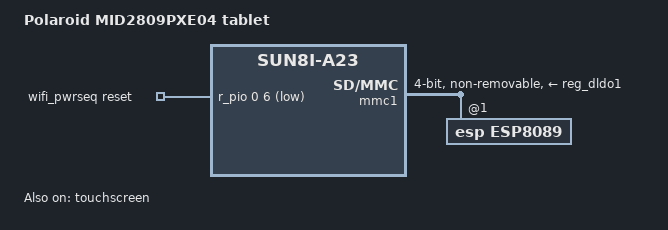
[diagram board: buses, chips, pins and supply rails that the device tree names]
/dts-v1/;
#include "sun8i-a23.dtsi"
#include "sun8i-reference-design-tablet.dtsi"
/ {
	model = "Polaroid MID2809PXE04 tablet";
	compatible = "polaroid,mid2809pxe04", "allwinner,sun8i-a23";
	aliases {
		ethernet0 = &esp8089;
	};
	wifi_pwrseq: wifi_pwrseq {
		compatible = "mmc-pwrseq-simple";
		reset-gpios = <&r_pio 0 6 GPIO_ACTIVE_LOW>;  
		post-power-on-delay-ms = <200>;
	};
};
&mmc1 {
	pinctrl-names = "default";
	pinctrl-0 = <&mmc1_pg_pins>;
	vmmc-supply = <&reg_dldo1>;
	mmc-pwrseq = <&wifi_pwrseq>;
	bus-width = <4>;
	non-removable;
	status = "okay";
	esp8089: sdio_wifi@1 {
		compatible = "esp,esp8089";
		reg = <1>;
		esp,crystal-26M-en = <2>;
	};
};
&touchscreen {
	reg = <0x40>;
	compatible = "silead,gsl3670";
	firmware-name = "gsl3670-polaroid-mid2809pxe04.fw";
	touchscreen-size-x = <1660>;
	touchscreen-size-y = <890>;
	status = "okay";
};
